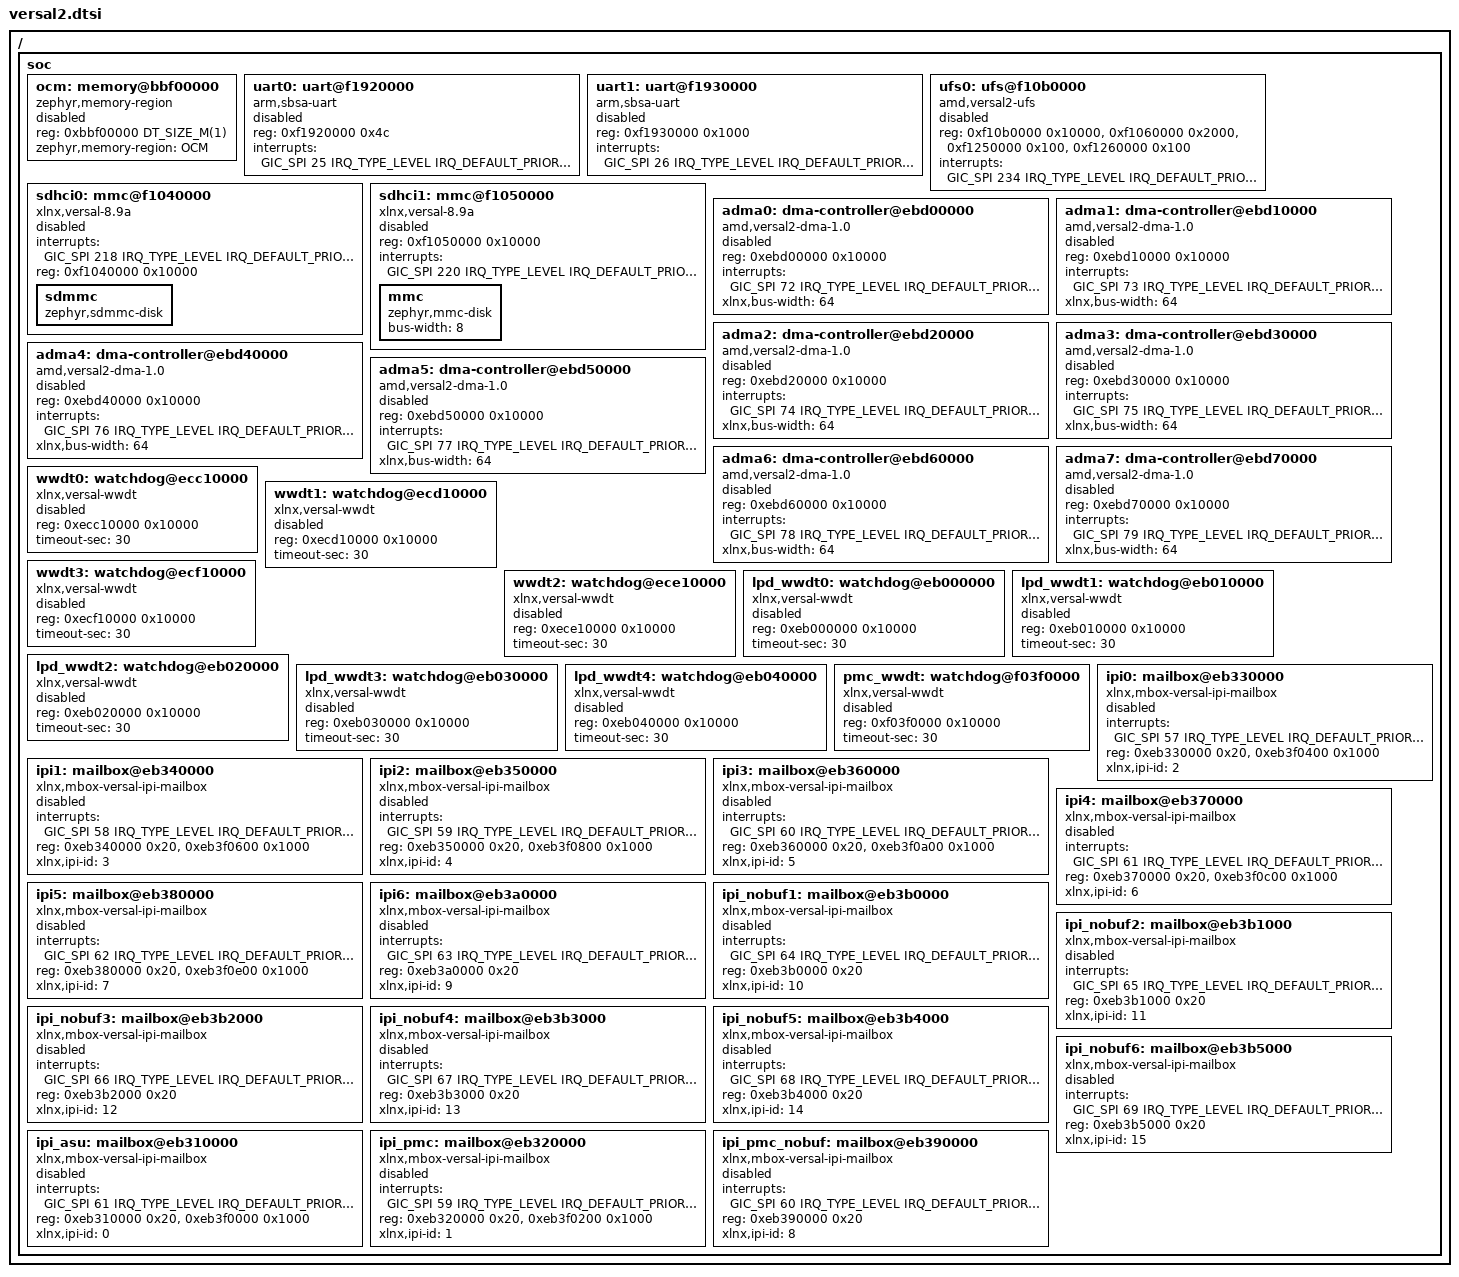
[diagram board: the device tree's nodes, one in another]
// SPDX-License-Identifier: GPL-2.0
/*
 * (C) Copyright 2025, Advanced Micro Devices, Inc.
 *
 * Mubin Sayyed <mubin.sayyed@amd.com>
 */

/ {
	soc: soc {
		ocm: memory@bbf00000 {
			compatible = "zephyr,memory-region";
			reg = <0xbbf00000 DT_SIZE_M(1)>;
			status = "disabled";
			zephyr,memory-region = "OCM";
		};

		uart0: uart@f1920000 {
			compatible = "arm,sbsa-uart";
			reg = <0xf1920000 0x4c>;
			status = "disabled";
			interrupt-names = "irq_0";
			interrupts = <GIC_SPI 25 IRQ_TYPE_LEVEL IRQ_DEFAULT_PRIORITY>;
		};

		uart1: uart@f1930000 {
			compatible = "arm,sbsa-uart";
			reg = <0xf1930000 0x1000>;
			status = "disabled";
			interrupt-names = "irq_1";
			interrupts = <GIC_SPI 26 IRQ_TYPE_LEVEL IRQ_DEFAULT_PRIORITY>;
		};

		ufs0: ufs@f10b0000 {
			compatible = "amd,versal2-ufs";
			status = "disabled";
			reg = <0xf10b0000 0x10000>,
			      <0xf1060000 0x2000>,
			      <0xf1250000 0x100>,
			      <0xf1260000 0x100>;
			interrupts = <GIC_SPI 234 IRQ_TYPE_LEVEL IRQ_DEFAULT_PRIORITY>;
		};

		sdhci0: mmc@f1040000 {
			compatible = "xlnx,versal-8.9a";
			status = "disabled";
			interrupts = <GIC_SPI 218 IRQ_TYPE_LEVEL IRQ_DEFAULT_PRIORITY>;
			reg = <0xf1040000 0x10000>;
			sdmmc {
				compatible = "zephyr,sdmmc-disk";
			};
		};

		sdhci1: mmc@f1050000 {
			compatible = "xlnx,versal-8.9a";
			status = "disabled";
			reg = <0xf1050000 0x10000>;
			interrupts = <GIC_SPI 220 IRQ_TYPE_LEVEL IRQ_DEFAULT_PRIORITY>;
			mmc {
				bus-width = <8>;
				compatible = "zephyr,mmc-disk";
			};
		};

		adma0: dma-controller@ebd00000 {
			compatible = "amd,versal2-dma-1.0";
			status = "disabled";
			reg = <0xebd00000 0x10000>;
			#dma-cells = <1>;
			interrupts = <GIC_SPI 72 IRQ_TYPE_LEVEL
					IRQ_DEFAULT_PRIORITY>;
			clock-names = "clk_main", "clk_apb";
			xlnx,bus-width = <64>;
		};

		adma1: dma-controller@ebd10000 {
			compatible = "amd,versal2-dma-1.0";
			status = "disabled";
			reg = <0xebd10000 0x10000>;
			#dma-cells = <1>;
			interrupts = <GIC_SPI 73 IRQ_TYPE_LEVEL
					IRQ_DEFAULT_PRIORITY>;
			clock-names = "clk_main", "clk_apb";
			xlnx,bus-width = <64>;
		};

		adma2: dma-controller@ebd20000 {
			compatible = "amd,versal2-dma-1.0";
			status = "disabled";
			reg = <0xebd20000 0x10000>;
			#dma-cells = <1>;
			interrupts = <GIC_SPI 74 IRQ_TYPE_LEVEL
					IRQ_DEFAULT_PRIORITY>;
			clock-names = "clk_main", "clk_apb";
			xlnx,bus-width = <64>;
		};

		adma3: dma-controller@ebd30000 {
			compatible = "amd,versal2-dma-1.0";
			status = "disabled";
			reg = <0xebd30000 0x10000>;
			#dma-cells = <1>;
			interrupts = <GIC_SPI 75 IRQ_TYPE_LEVEL
					IRQ_DEFAULT_PRIORITY>;
			clock-names = "clk_main", "clk_apb";
			xlnx,bus-width = <64>;
		};

		adma4: dma-controller@ebd40000 {
			compatible = "amd,versal2-dma-1.0";
			status = "disabled";
			reg = <0xebd40000 0x10000>;
			#dma-cells = <1>;
			interrupts = <GIC_SPI 76 IRQ_TYPE_LEVEL
					IRQ_DEFAULT_PRIORITY>;
			clock-names = "clk_main", "clk_apb";
			xlnx,bus-width = <64>;
		};

		adma5: dma-controller@ebd50000 {
			compatible = "amd,versal2-dma-1.0";
			status = "disabled";
			reg = <0xebd50000 0x10000>;
			#dma-cells = <1>;
			interrupts = <GIC_SPI 77 IRQ_TYPE_LEVEL
					IRQ_DEFAULT_PRIORITY>;
			clock-names = "clk_main", "clk_apb";
			xlnx,bus-width = <64>;
		};

		adma6: dma-controller@ebd60000 {
			compatible = "amd,versal2-dma-1.0";
			status = "disabled";
			reg = <0xebd60000 0x10000>;
			#dma-cells = <1>;
			interrupts = <GIC_SPI 78 IRQ_TYPE_LEVEL
					IRQ_DEFAULT_PRIORITY>;
			clock-names = "clk_main", "clk_apb";
			xlnx,bus-width = <64>;
		};

		adma7: dma-controller@ebd70000 {
			compatible = "amd,versal2-dma-1.0";
			status = "disabled";
			reg = <0xebd70000 0x10000>;
			#dma-cells = <1>;
			interrupts = <GIC_SPI 79 IRQ_TYPE_LEVEL
					IRQ_DEFAULT_PRIORITY>;
			clock-names = "clk_main", "clk_apb";
			xlnx,bus-width = <64>;
		};

		wwdt0: watchdog@ecc10000 {
			compatible = "xlnx,versal-wwdt";
			status = "disabled";
			reg = <0xecc10000 0x10000>;
			timeout-sec = <30>;
		};

		wwdt1: watchdog@ecd10000 {
			compatible = "xlnx,versal-wwdt";
			status = "disabled";
			reg = <0xecd10000 0x10000>;
			timeout-sec = <30>;
		};

		wwdt2: watchdog@ece10000 {
			compatible = "xlnx,versal-wwdt";
			status = "disabled";
			reg = <0xece10000 0x10000>;
			timeout-sec = <30>;
		};

		wwdt3: watchdog@ecf10000 {
			compatible = "xlnx,versal-wwdt";
			status = "disabled";
			reg = <0xecf10000 0x10000>;
			timeout-sec = <30>;
		};

		lpd_wwdt0: watchdog@eb000000 {
			compatible = "xlnx,versal-wwdt";
			status = "disabled";
			reg = <0xeb000000 0x10000>;
			timeout-sec = <30>;
		};

		lpd_wwdt1: watchdog@eb010000 {
			compatible = "xlnx,versal-wwdt";
			status = "disabled";
			reg = <0xeb010000 0x10000>;
			timeout-sec = <30>;
		};

		lpd_wwdt2: watchdog@eb020000 {
			compatible = "xlnx,versal-wwdt";
			status = "disabled";
			reg = <0xeb020000 0x10000>;
			timeout-sec = <30>;
		};

		lpd_wwdt3: watchdog@eb030000 {
			compatible = "xlnx,versal-wwdt";
			status = "disabled";
			reg = <0xeb030000 0x10000>;
			timeout-sec = <30>;
		};

		lpd_wwdt4: watchdog@eb040000 {
			compatible = "xlnx,versal-wwdt";
			status = "disabled";
			reg = <0xeb040000 0x10000>;
			timeout-sec = <30>;
		};

		pmc_wwdt: watchdog@f03f0000 {
			compatible = "xlnx,versal-wwdt";
			status = "disabled";
			reg = <0xf03f0000 0x10000>;
			timeout-sec = <30>;
		};

		ipi0: mailbox@eb330000 {
			compatible = "xlnx,mbox-versal-ipi-mailbox";
			status = "disabled";
			interrupts = <GIC_SPI 57 IRQ_TYPE_LEVEL IRQ_DEFAULT_PRIORITY>;
			reg = <0xeb330000 0x20>, <0xeb3f0400 0x1000>;
			reg-names = "ctrl", "msg";
			xlnx,ipi-id = <2>;
			#address-cells = <1>;
			#size-cells = <1>;
		};

		ipi1: mailbox@eb340000 {
			compatible = "xlnx,mbox-versal-ipi-mailbox";
			status = "disabled";
			interrupts = <GIC_SPI 58 IRQ_TYPE_LEVEL IRQ_DEFAULT_PRIORITY>;
			reg = <0xeb340000 0x20>, <0xeb3f0600 0x1000>;
			reg-names = "ctrl", "msg";
			xlnx,ipi-id = <3>;
			#address-cells = <1>;
			#size-cells = <1>;
		};

		ipi2: mailbox@eb350000 {
			compatible = "xlnx,mbox-versal-ipi-mailbox";
			status = "disabled";
			interrupts = <GIC_SPI 59 IRQ_TYPE_LEVEL IRQ_DEFAULT_PRIORITY>;
			reg = <0xeb350000 0x20>, <0xeb3f0800 0x1000>;
			reg-names = "ctrl", "msg";
			xlnx,ipi-id = <4>;
			#address-cells = <1>;
			#size-cells = <1>;
		};

		ipi3: mailbox@eb360000 {
			compatible = "xlnx,mbox-versal-ipi-mailbox";
			status = "disabled";
			interrupts = <GIC_SPI 60 IRQ_TYPE_LEVEL IRQ_DEFAULT_PRIORITY>;
			reg = <0xeb360000 0x20>, <0xeb3f0a00 0x1000>;
			reg-names = "ctrl", "msg";
			xlnx,ipi-id = <5>;
			#address-cells = <1>;
			#size-cells = <1>;
		};

		ipi4: mailbox@eb370000 {
			compatible = "xlnx,mbox-versal-ipi-mailbox";
			status = "disabled";
			interrupts = <GIC_SPI 61 IRQ_TYPE_LEVEL IRQ_DEFAULT_PRIORITY>;
			reg = <0xeb370000 0x20>, <0xeb3f0c00 0x1000>;
			reg-names = "ctrl", "msg";
			xlnx,ipi-id = <6>;
			#address-cells = <1>;
			#size-cells = <1>;
		};

		ipi5: mailbox@eb380000 {
			compatible = "xlnx,mbox-versal-ipi-mailbox";
			status = "disabled";
			interrupts = <GIC_SPI 62 IRQ_TYPE_LEVEL IRQ_DEFAULT_PRIORITY>;
			reg = <0xeb380000 0x20>, <0xeb3f0e00 0x1000>;
			reg-names = "ctrl", "msg";
			xlnx,ipi-id = <7>;
			#address-cells = <1>;
			#size-cells = <1>;
		};

		ipi6: mailbox@eb3a0000 {
			compatible = "xlnx,mbox-versal-ipi-mailbox";
			status = "disabled";
			interrupts = <GIC_SPI 63 IRQ_TYPE_LEVEL IRQ_DEFAULT_PRIORITY>;
			reg = <0xeb3a0000 0x20>;
			reg-names = "ctrl";
			xlnx,ipi-id = <9>;
			#address-cells = <1>;
			#size-cells = <1>;
		};

		ipi_nobuf1: mailbox@eb3b0000 {
			compatible = "xlnx,mbox-versal-ipi-mailbox";
			status = "disabled";
			interrupts = <GIC_SPI 64 IRQ_TYPE_LEVEL IRQ_DEFAULT_PRIORITY>;
			reg = <0xeb3b0000 0x20>;
			reg-names = "ctrl";
			xlnx,ipi-id = <10>;
			#address-cells = <1>;
			#size-cells = <1>;
		};

		ipi_nobuf2: mailbox@eb3b1000 {
			compatible = "xlnx,mbox-versal-ipi-mailbox";
			status = "disabled";
			interrupts = <GIC_SPI 65 IRQ_TYPE_LEVEL IRQ_DEFAULT_PRIORITY>;
			reg = <0xeb3b1000 0x20>;
			reg-names = "ctrl";
			xlnx,ipi-id = <11>;
			#address-cells = <1>;
			#size-cells = <1>;
		};

		ipi_nobuf3: mailbox@eb3b2000 {
			compatible = "xlnx,mbox-versal-ipi-mailbox";
			status = "disabled";
			interrupts = <GIC_SPI 66 IRQ_TYPE_LEVEL IRQ_DEFAULT_PRIORITY>;
			reg = <0xeb3b2000 0x20>;
			reg-names = "ctrl";
			xlnx,ipi-id = <12>;
			#address-cells = <1>;
			#size-cells = <1>;
		};

		ipi_nobuf4: mailbox@eb3b3000 {
			compatible = "xlnx,mbox-versal-ipi-mailbox";
			status = "disabled";
			interrupts = <GIC_SPI 67 IRQ_TYPE_LEVEL IRQ_DEFAULT_PRIORITY>;
			reg = <0xeb3b3000 0x20>;
			reg-names = "ctrl";
			xlnx,ipi-id = <13>;
			#address-cells = <1>;
			#size-cells = <1>;
		};

		ipi_nobuf5: mailbox@eb3b4000 {
			compatible = "xlnx,mbox-versal-ipi-mailbox";
			status = "disabled";
			interrupts = <GIC_SPI 68 IRQ_TYPE_LEVEL IRQ_DEFAULT_PRIORITY>;
			reg = <0xeb3b4000 0x20>;
			reg-names = "ctrl";
			xlnx,ipi-id = <14>;
			#address-cells = <1>;
			#size-cells = <1>;
		};

		ipi_nobuf6: mailbox@eb3b5000 {
			compatible = "xlnx,mbox-versal-ipi-mailbox";
			status = "disabled";
			interrupts = <GIC_SPI 69 IRQ_TYPE_LEVEL IRQ_DEFAULT_PRIORITY>;
			reg = <0xeb3b5000 0x20>;
			reg-names = "ctrl";
			xlnx,ipi-id = <15>;
			#address-cells = <1>;
			#size-cells = <1>;
		};

		ipi_asu: mailbox@eb310000 {
			compatible = "xlnx,mbox-versal-ipi-mailbox";
			status = "disabled";
			interrupts = <GIC_SPI 61 IRQ_TYPE_LEVEL IRQ_DEFAULT_PRIORITY>;
			reg = <0xeb310000 0x20>, <0xeb3f0000 0x1000>;
			reg-names = "ctrl", "msg";
			xlnx,ipi-id = <0>;
			#address-cells = <1>;
			#size-cells = <1>;
		};

		ipi_pmc: mailbox@eb320000 {
			compatible = "xlnx,mbox-versal-ipi-mailbox";
			status = "disabled";
			interrupts = <GIC_SPI 59 IRQ_TYPE_LEVEL IRQ_DEFAULT_PRIORITY>;
			reg = <0xeb320000 0x20>, <0xeb3f0200 0x1000>;
			reg-names = "ctrl", "msg";
			xlnx,ipi-id = <1>;
			#address-cells = <1>;
			#size-cells = <1>;
		};

		ipi_pmc_nobuf: mailbox@eb390000 {
			compatible = "xlnx,mbox-versal-ipi-mailbox";
			status = "disabled";
			interrupts = <GIC_SPI 60 IRQ_TYPE_LEVEL IRQ_DEFAULT_PRIORITY>;
			reg = <0xeb390000 0x20>;
			reg-names = "ctrl";
			xlnx,ipi-id = <8>;
			#address-cells = <1>;
			#size-cells = <1>;
		};
	};
};
